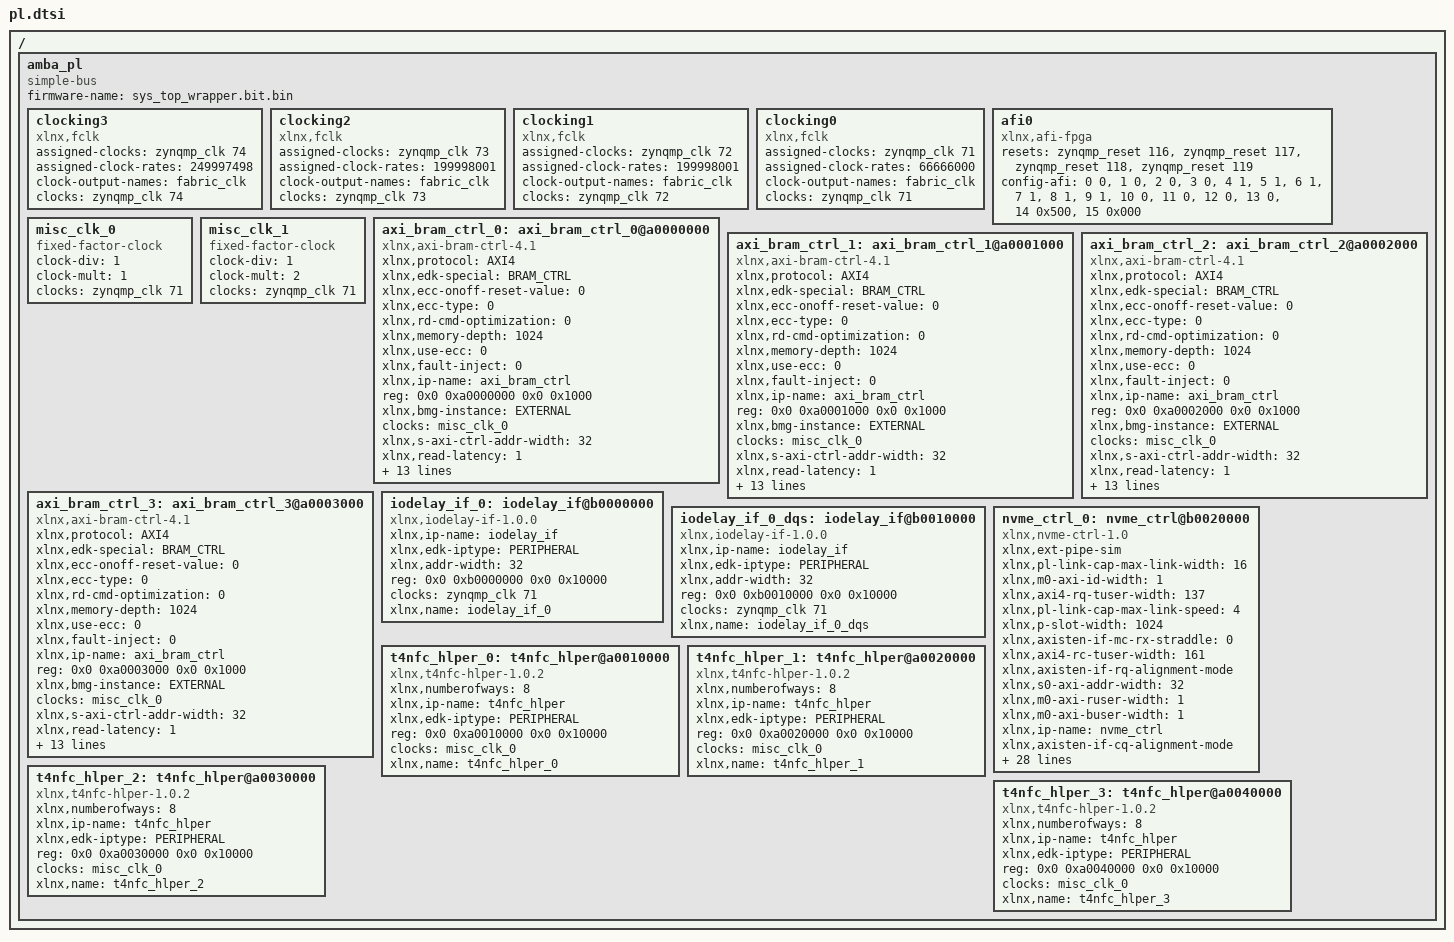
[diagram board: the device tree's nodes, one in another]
/ {
	amba_pl: amba_pl {
		ranges;
		compatible = "simple-bus";
		#address-cells = <2>;
		#size-cells = <2>;
		firmware-name = "sys_top_wrapper.bit.bin";
		clocking3: clocking3 {
			compatible = "xlnx,fclk";
			status = "okay";
			assigned-clocks = <&zynqmp_clk 74>;
			assigned-clock-rates = <249997498>;
			#clock-cells = <0>;
			clock-output-names = "fabric_clk";
			clocks = <&zynqmp_clk 74>;
		};
		clocking2: clocking2 {
			compatible = "xlnx,fclk";
			status = "okay";
			assigned-clocks = <&zynqmp_clk 73>;
			assigned-clock-rates = <199998001>;
			#clock-cells = <0>;
			clock-output-names = "fabric_clk";
			clocks = <&zynqmp_clk 73>;
		};
		clocking1: clocking1 {
			compatible = "xlnx,fclk";
			status = "okay";
			assigned-clocks = <&zynqmp_clk 72>;
			assigned-clock-rates = <199998001>;
			#clock-cells = <0>;
			clock-output-names = "fabric_clk";
			clocks = <&zynqmp_clk 72>;
		};
		clocking0: clocking0 {
			compatible = "xlnx,fclk";
			status = "okay";
			assigned-clocks = <&zynqmp_clk 71>;
			assigned-clock-rates = <66666000>;
			#clock-cells = <0>;
			clock-output-names = "fabric_clk";
			clocks = <&zynqmp_clk 71>;
		};
		afi0: afi0 {
			status = "okay";
			compatible = "xlnx,afi-fpga";
			resets = <&zynqmp_reset 116>, <&zynqmp_reset 117>, <&zynqmp_reset 118>, <&zynqmp_reset 119>;
			config-afi = < 0 0>, <1 0>, <2 0>, <3 0>, <4 1>, <5 1>, <6 1>, <7 1>, <8 1>, <9 1>, <10 0>, <11 0>, <12 0>, <13 0>, <14 0x500>, <15 0x000>;
		};
		misc_clk_0: misc_clk_0 {
			clock-div = <1>;
			compatible = "fixed-factor-clock";
			clock-mult = <1>;
			clocks = <&zynqmp_clk 71>;
			#clock-cells = <0>;
		};
		misc_clk_1: misc_clk_1 {
			clock-div = <1>;
			compatible = "fixed-factor-clock";
			clock-mult = <2>;
			clocks = <&zynqmp_clk 71>;
			#clock-cells = <0>;
		};
		axi_bram_ctrl_0: axi_bram_ctrl_0@a0000000 {
			xlnx,protocol = "AXI4";
			xlnx,edk-special = "BRAM_CTRL";
			compatible = "xlnx,axi-bram-ctrl-4.1" , "xlnx,axi-bram-ctrl";
			xlnx,ecc-onoff-reset-value = <0>;
			xlnx,ecc-type = <0>;
			xlnx,rd-cmd-optimization = <0>;
			xlnx,memory-depth = <1024>;
			xlnx,use-ecc = <0>;
			xlnx,fault-inject = <0>;
			xlnx,ip-name = "axi_bram_ctrl";
			reg = <0x0 0xa0000000 0x0 0x1000>;
			xlnx,bmg-instance = "EXTERNAL";
			clocks = <&misc_clk_0>;
			xlnx,s-axi-ctrl-addr-width = <32>;
			xlnx,read-latency = <1>;
			xlnx,id-width = <0>;
			xlnx,s-axi-supports-narrow-burst = <1>;
			xlnx,supports-narrow-burst = <1>;
			xlnx,single-port-bram = <1>;
			xlnx,ecc = <0>;
			xlnx,edk-iptype = "PERIPHERAL";
			status = "okay";
			clock-names = "s_axi_aclk";
			xlnx,data-width = <32>;
			xlnx,bram-addr-width = <10>;
			xlnx,bram-inst-mode = "EXTERNAL";
			xlnx,s-axi-ctrl-data-width = <32>;
			xlnx,mem-depth = <1024>;
			xlnx,s-axi-id-width = <1>;
			xlnx,name = "axi_bram_ctrl_0";
		};
		axi_bram_ctrl_1: axi_bram_ctrl_1@a0001000 {
			xlnx,protocol = "AXI4";
			xlnx,edk-special = "BRAM_CTRL";
			compatible = "xlnx,axi-bram-ctrl-4.1" , "xlnx,axi-bram-ctrl";
			xlnx,ecc-onoff-reset-value = <0>;
			xlnx,ecc-type = <0>;
			xlnx,rd-cmd-optimization = <0>;
			xlnx,memory-depth = <1024>;
			xlnx,use-ecc = <0>;
			xlnx,fault-inject = <0>;
			xlnx,ip-name = "axi_bram_ctrl";
			reg = <0x0 0xa0001000 0x0 0x1000>;
			xlnx,bmg-instance = "EXTERNAL";
			clocks = <&misc_clk_0>;
			xlnx,s-axi-ctrl-addr-width = <32>;
			xlnx,read-latency = <1>;
			xlnx,id-width = <0>;
			xlnx,s-axi-supports-narrow-burst = <1>;
			xlnx,supports-narrow-burst = <1>;
			xlnx,single-port-bram = <1>;
			xlnx,ecc = <0>;
			xlnx,edk-iptype = "PERIPHERAL";
			status = "okay";
			clock-names = "s_axi_aclk";
			xlnx,data-width = <32>;
			xlnx,bram-addr-width = <10>;
			xlnx,bram-inst-mode = "EXTERNAL";
			xlnx,s-axi-ctrl-data-width = <32>;
			xlnx,mem-depth = <1024>;
			xlnx,s-axi-id-width = <1>;
			xlnx,name = "axi_bram_ctrl_1";
		};
		axi_bram_ctrl_2: axi_bram_ctrl_2@a0002000 {
			xlnx,protocol = "AXI4";
			xlnx,edk-special = "BRAM_CTRL";
			compatible = "xlnx,axi-bram-ctrl-4.1" , "xlnx,axi-bram-ctrl";
			xlnx,ecc-onoff-reset-value = <0>;
			xlnx,ecc-type = <0>;
			xlnx,rd-cmd-optimization = <0>;
			xlnx,memory-depth = <1024>;
			xlnx,use-ecc = <0>;
			xlnx,fault-inject = <0>;
			xlnx,ip-name = "axi_bram_ctrl";
			reg = <0x0 0xa0002000 0x0 0x1000>;
			xlnx,bmg-instance = "EXTERNAL";
			clocks = <&misc_clk_0>;
			xlnx,s-axi-ctrl-addr-width = <32>;
			xlnx,read-latency = <1>;
			xlnx,id-width = <0>;
			xlnx,s-axi-supports-narrow-burst = <1>;
			xlnx,supports-narrow-burst = <1>;
			xlnx,single-port-bram = <1>;
			xlnx,ecc = <0>;
			xlnx,edk-iptype = "PERIPHERAL";
			status = "okay";
			clock-names = "s_axi_aclk";
			xlnx,data-width = <32>;
			xlnx,bram-addr-width = <10>;
			xlnx,bram-inst-mode = "EXTERNAL";
			xlnx,s-axi-ctrl-data-width = <32>;
			xlnx,mem-depth = <1024>;
			xlnx,s-axi-id-width = <1>;
			xlnx,name = "axi_bram_ctrl_2";
		};
		axi_bram_ctrl_3: axi_bram_ctrl_3@a0003000 {
			xlnx,protocol = "AXI4";
			xlnx,edk-special = "BRAM_CTRL";
			compatible = "xlnx,axi-bram-ctrl-4.1" , "xlnx,axi-bram-ctrl";
			xlnx,ecc-onoff-reset-value = <0>;
			xlnx,ecc-type = <0>;
			xlnx,rd-cmd-optimization = <0>;
			xlnx,memory-depth = <1024>;
			xlnx,use-ecc = <0>;
			xlnx,fault-inject = <0>;
			xlnx,ip-name = "axi_bram_ctrl";
			reg = <0x0 0xa0003000 0x0 0x1000>;
			xlnx,bmg-instance = "EXTERNAL";
			clocks = <&misc_clk_0>;
			xlnx,s-axi-ctrl-addr-width = <32>;
			xlnx,read-latency = <1>;
			xlnx,id-width = <0>;
			xlnx,s-axi-supports-narrow-burst = <1>;
			xlnx,supports-narrow-burst = <1>;
			xlnx,single-port-bram = <1>;
			xlnx,ecc = <0>;
			xlnx,edk-iptype = "PERIPHERAL";
			status = "okay";
			clock-names = "s_axi_aclk";
			xlnx,data-width = <32>;
			xlnx,bram-addr-width = <10>;
			xlnx,bram-inst-mode = "EXTERNAL";
			xlnx,s-axi-ctrl-data-width = <32>;
			xlnx,mem-depth = <1024>;
			xlnx,s-axi-id-width = <1>;
			xlnx,name = "axi_bram_ctrl_3";
		};
		iodelay_if_0: iodelay_if@b0000000 {
			compatible = "xlnx,iodelay-if-1.0.0";
			status = "okay";
			clock-names = "sys__clk";
			xlnx,ip-name = "iodelay_if";
			xlnx,edk-iptype = "PERIPHERAL";
			xlnx,addr-width = <32>;
			reg = <0x0 0xb0000000 0x0 0x10000>;
			clocks = <&zynqmp_clk 71>;
			xlnx,name = "iodelay_if_0";
		};
		iodelay_if_0_dqs: iodelay_if@b0010000 {
			compatible = "xlnx,iodelay-if-1.0.0";
			status = "okay";
			clock-names = "sys__clk";
			xlnx,ip-name = "iodelay_if";
			xlnx,edk-iptype = "PERIPHERAL";
			xlnx,addr-width = <32>;
			reg = <0x0 0xb0010000 0x0 0x10000>;
			clocks = <&zynqmp_clk 71>;
			xlnx,name = "iodelay_if_0_dqs";
		};
		nvme_ctrl_0: nvme_ctrl@b0020000 {
			xlnx,ext-pipe-sim;
			compatible = "xlnx,nvme-ctrl-1.0";
			xlnx,pl-link-cap-max-link-width = <16>;
			xlnx,m0-axi-id-width = <1>;
			xlnx,axi4-rq-tuser-width = <137>;
			xlnx,pl-link-cap-max-link-speed = <4>;
			xlnx,p-slot-width = <1024>;
			xlnx,axisten-if-mc-rx-straddle = <0>;
			xlnx,axi4-rc-tuser-width = <161>;
			xlnx,axisten-if-rq-alignment-mode;
			xlnx,s0-axi-addr-width = <32>;
			xlnx,m0-axi-ruser-width = <1>;
			xlnx,m0-axi-buser-width = <1>;
			xlnx,ip-name = "nvme_ctrl";
			xlnx,axisten-if-cq-alignment-mode;
			xlnx,rq-avail-tag-idx = <8>;
			xlnx,m0-axi-data-width = <64>;
			xlnx,m0-axi-aruser-width = <1>;
			xlnx,axisten-if-rc-alignment-mode;
			reg = <0x0 0xb0020000 0x0 0x20000>;
			clocks = <&zynqmp_clk 74>, <&misc_clk_1>, <&misc_clk_1>, <&zynqmp_clk 73>;
			xlnx,axisten-if-rq-parity-check = <0>;
			xlnx,axisten-if-cc-alignment-mode;
			xlnx,keep-width = <16>;
			xlnx,axisten-if-cq-parity-check = <0>;
			xlnx,axisten-if-rc-parity-check = <0>;
			xlnx,edk-iptype = "PERIPHERAL";
			xlnx,m0-axi-wuser-width = <1>;
			xlnx,axisten-if-enable-msg-route = "101111111111111111";
			xlnx,axi4-cq-tuser-width = <183>;
			xlnx,axisten-if-cc-parity-check = <0>;
			xlnx,p-slot-tag-width = <10>;
			xlnx,pcie-data-width = <512>;
			xlnx,m0-axi-awuser-width = <1>;
			xlnx,rq-avail-tag = <256>;
			xlnx,s0-axi-data-width = <32>;
			status = "okay";
			xlnx,axi4-cc-tuser-width = <81>;
			clock-names = "m0_axi_aclk" , "pcie_ref_clk_n" , "pcie_ref_clk_p" , "s0_axi_aclk";
			xlnx,axisten-if-enable-rx-msg-intfc;
			xlnx,m0-axi-addr-width = <32>;
			xlnx,axisten-if-enable-client-tag = <1>;
			xlnx,name = "nvme_ctrl_0";
		};
		t4nfc_hlper_0: t4nfc_hlper@a0010000 {
			xlnx,numberofways = <8>;
			compatible = "xlnx,t4nfc-hlper-1.0.2";
			status = "okay";
			clock-names = "iClock";
			xlnx,ip-name = "t4nfc_hlper";
			xlnx,edk-iptype = "PERIPHERAL";
			reg = <0x0 0xa0010000 0x0 0x10000>;
			clocks = <&misc_clk_0>;
			xlnx,name = "t4nfc_hlper_0";
		};
		t4nfc_hlper_1: t4nfc_hlper@a0020000 {
			xlnx,numberofways = <8>;
			compatible = "xlnx,t4nfc-hlper-1.0.2";
			status = "okay";
			clock-names = "iClock";
			xlnx,ip-name = "t4nfc_hlper";
			xlnx,edk-iptype = "PERIPHERAL";
			reg = <0x0 0xa0020000 0x0 0x10000>;
			clocks = <&misc_clk_0>;
			xlnx,name = "t4nfc_hlper_1";
		};
		t4nfc_hlper_2: t4nfc_hlper@a0030000 {
			xlnx,numberofways = <8>;
			compatible = "xlnx,t4nfc-hlper-1.0.2";
			status = "okay";
			clock-names = "iClock";
			xlnx,ip-name = "t4nfc_hlper";
			xlnx,edk-iptype = "PERIPHERAL";
			reg = <0x0 0xa0030000 0x0 0x10000>;
			clocks = <&misc_clk_0>;
			xlnx,name = "t4nfc_hlper_2";
		};
		t4nfc_hlper_3: t4nfc_hlper@a0040000 {
			xlnx,numberofways = <8>;
			compatible = "xlnx,t4nfc-hlper-1.0.2";
			status = "okay";
			clock-names = "iClock";
			xlnx,ip-name = "t4nfc_hlper";
			xlnx,edk-iptype = "PERIPHERAL";
			reg = <0x0 0xa0040000 0x0 0x10000>;
			clocks = <&misc_clk_0>;
			xlnx,name = "t4nfc_hlper_3";
		};
	};
};
